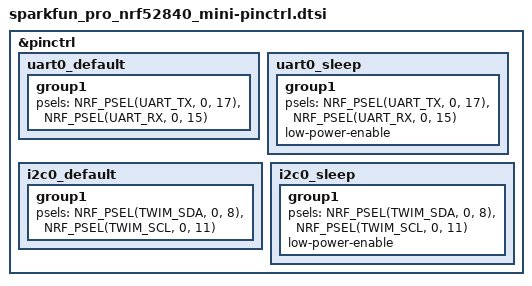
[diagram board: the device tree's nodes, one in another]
/*
 * SparkFun Pro nRF52840 Mini (DEV-15025) default pin assignments.
 *
 * UART pins match the silkscreen (TX = P0.17, RX = P0.15).
 * I2C pins are the Qwiic connector (SDA = P0.08, SCL = P0.11), which has
 * 2.2 k pull-ups to 3.3 V on the board.
 *
 * SPDX-License-Identifier: Apache-2.0
 */

&pinctrl {
	uart0_default: uart0_default {
		group1 {
			psels = <NRF_PSEL(UART_TX, 0, 17)>,
				<NRF_PSEL(UART_RX, 0, 15)>;
		};
	};

	uart0_sleep: uart0_sleep {
		group1 {
			psels = <NRF_PSEL(UART_TX, 0, 17)>,
				<NRF_PSEL(UART_RX, 0, 15)>;
			low-power-enable;
		};
	};

	i2c0_default: i2c0_default {
		group1 {
			psels = <NRF_PSEL(TWIM_SDA, 0, 8)>,
				<NRF_PSEL(TWIM_SCL, 0, 11)>;
		};
	};

	i2c0_sleep: i2c0_sleep {
		group1 {
			psels = <NRF_PSEL(TWIM_SDA, 0, 8)>,
				<NRF_PSEL(TWIM_SCL, 0, 11)>;
			low-power-enable;
		};
	};
};
